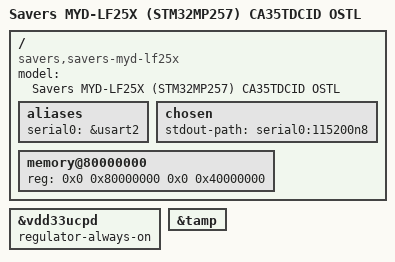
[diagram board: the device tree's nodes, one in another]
// SPDX-License-Identifier: (GPL-2.0-only OR BSD-3-Clause)
/*
 * Copyright (C) Savers 2024 - All Rights Reserved
 *
 * Savers MYD-LF25X (OP-TEE / CA35TDCID OSTL).
 *
 * Re-based onto MYiR's vanilla myb-stm32mp257x-1GB device tree. The SoM-level
 * secure configuration (STPMIC2, SCMI regulators, RIF/RISAF firewall, M33
 * remoteproc, RCC, TAMP, OTP shadow) all comes from MYiR's known-good base
 * (myb-stm32mp257x-base.dtsi + -rcc.dtsi + -rif.dtsi) instead of a
 * STM32MP257F-DK copy.
 *
 * SoM: MYiR MYD-LF25X, STM32MP257F (AI package), 1GB LPDDR4 (1x8Gbits).
 */

/dts-v1/;

#include "myb-stm32mp257x-base.dtsi"
#include "myb-stm32mp257x-rcc.dtsi"
#include "myb-stm32mp257x-1GB-resmem.dtsi"
#include "myb-stm32mp257x-rif.dtsi"
#include "stm32mp25-pinctrl.dtsi"
#include "stm32mp25xxai-pinctrl.dtsi"

/ {
	model = "Savers MYD-LF25X (STM32MP257) CA35TDCID OSTL";
	compatible = "savers,savers-myd-lf25x", "st,myb-stm32mp257x-1GB",
		     "myir,myb-stm32mp257x-1GB", "myir,myd-lf25x", "st,stm32mp257";

	aliases {
		serial0 = &usart2;
	};

	chosen {
		stdout-path = "serial0:115200n8";
	};

	memory@80000000 {
		device_type = "memory";
		reg = <0x0 0x80000000 0x0 0x40000000>;
	};

};

/*
 * Keep the UCPD 3V3 rail up for the Cortex-M33.
 *
 * myb-stm32mp257x-base.dtsi already sets vdd33ucpd to "okay", but nothing on
 * the A35 side -- neither OP-TEE nor Linux -- consumes it, so an unclaimed
 * regulator can be turned off. The only user is M33 firmware driving UCPD for
 * USB-C CC detection, and it has no way to request the rail.
 *
 * Both M33-capable reference trees add this: MYIR's own
 * myb-stm32mp257x-1GB-ca35tdcid-ostl-m33-examples.dts and ST's
 * stm32mp257f-dk-ca35tdcid-ostl-m33-examples.dts. The plain (non-m33) variants
 * this board was derived from omit it, which is consistent with the symptom --
 * ST's USBPD_DRP_UCSI firmware boots and brings up rpmsg, but never announces
 * its rpmsg_i2c channel, so no UCSI interface is registered and Linux sees no
 * Type-C port.
 */
&vdd33ucpd {
	regulator-always-on;
};

&tamp {
	/delete-node/ tamp-button;
};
